VERSION ""

NS_ :

BS_:

BU_:

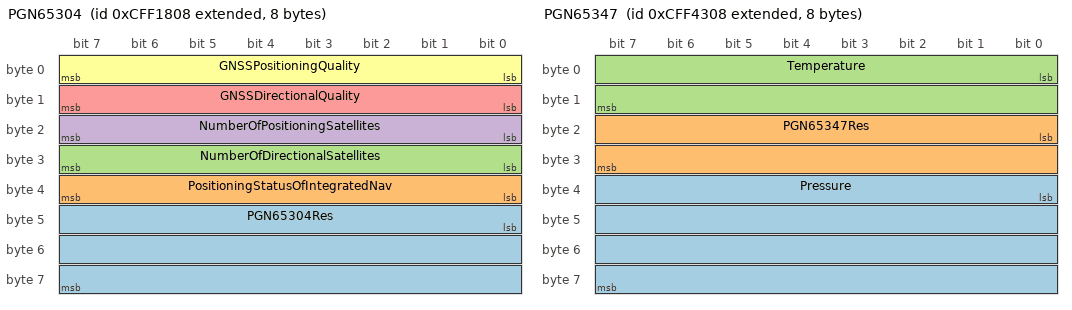
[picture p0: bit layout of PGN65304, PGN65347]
BO_ 2365528072 PGN65304: 8 Vector__XXX
 SG_ PGN65304Res : 40|24@1- (1,0) [0|0] "" Vector__XXX
 SG_ PositioningStatusOfIntegratedNav : 32|8@1- (1,0) [0|0] "" Vector__XXX
 SG_ NumberOfDirectionalSatellites : 24|8@1- (1,0) [0|0] "" Vector__XXX
 SG_ NumberOfPositioningSatellites : 16|8@1- (1,0) [0|0] "" Vector__XXX
 SG_ GNSSDirectionalQuality : 8|8@1- (1,0) [0|0] "" Vector__XXX
 SG_ GNSSPositioningQuality : 0|8@1- (1,0) [0|0] "" Vector__XXX

BO_ 2015 ODB2: 8 Vector__XXX
 SG_ Odometer : 0|64@1- (1,0) [0|0] "km/h" Vector__XXX

BO_ 2365539080 PGN65347: 8 Vector__XXX
 SG_ Pressure : 32|32@1- (0.01,0) [0|0] "Pa" Vector__XXX
SG_ PGN65347Res : 16|16@1- (1,0) [0|0] "" Vector__XXX
 SG_ Temperature : 0|16@1- (0.01,0) [0|0] "degC" Vector__XXX

BO_ 2365538568 PGN65345: 8 Vector__XXX
 SG_ PGN65345Res : 32|32@1- (1,0) [0|0] "" Vector__XXX
 SG_ Yaw : 0|32@1- (0.001,0) [0|0] "deg" Vector__XXX

BO_ 2365537544 PGN65341: 8 Vector__XXX
 SG_ Pitch : 32|32@1- (0.001,0) [0|0] "deg" Vector__XXX
 SG_ Roll : 0|32@1- (0.001,0) [0|0] "deg" Vector__XXX

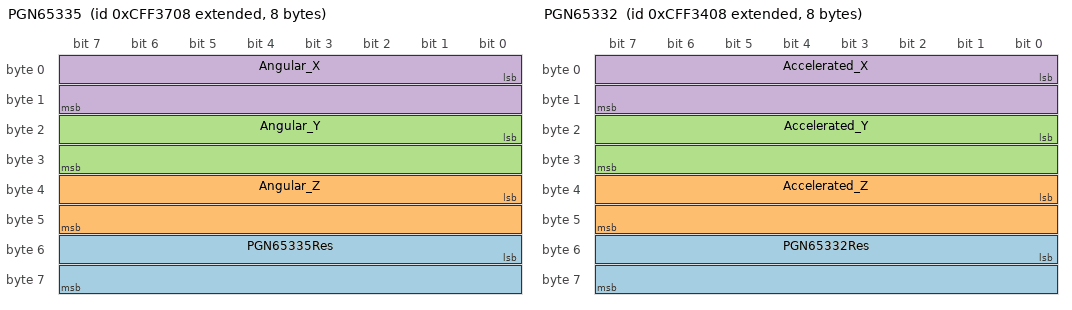
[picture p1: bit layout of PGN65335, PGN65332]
BO_ 2365536008 PGN65335: 8 Vector__XXX
 SG_ PGN65335Res : 48|16@1- (1,0) [0|0] "" Vector__XXX
 SG_ Angular_Z : 32|16@1- (0.061035,0) [0|0] "deg/s" Vector__XXX
 SG_ Angular_Y : 16|16@1- (0.061035,0) [0|0] "deg/s" Vector__XXX
 SG_ Angular_X : 0|16@1- (0.061035,0) [0|0] "deg/s" Vector__XXX

BO_ 2365535240 PGN65332: 8 Vector__XXX
 SG_ PGN65332Res : 48|16@1- (1,0) [0|0] "" Vector__XXX
 SG_ Accelerated_Z : 32|16@1- (0.00048828,0) [0|0] "G" Vector__XXX
 SG_ Accelerated_Y : 16|16@1- (0.00048828,0) [0|0] "G" Vector__XXX
 SG_ Accelerated_X : 0|16@1- (0.00048828,0) [0|0] "G" Vector__XXX

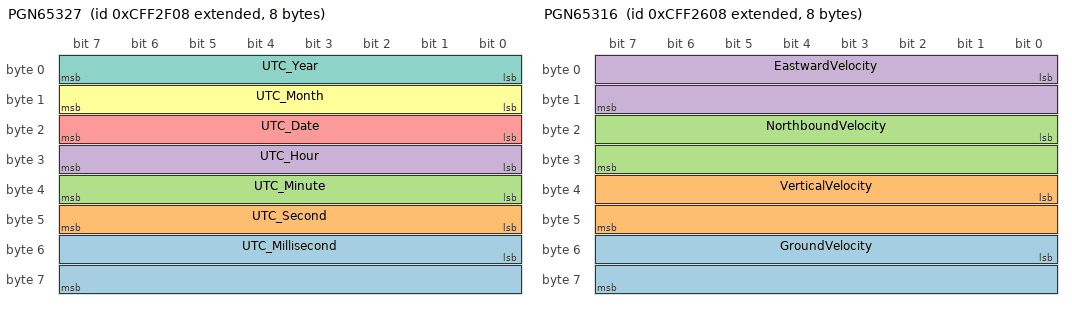
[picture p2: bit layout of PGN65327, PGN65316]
BO_ 2365533960 PGN65327: 8 Vector__XXX
 SG_ UTC_Millisecond : 48|16@1- (1,0) [0|0] "millisecond" Vector__XXX
 SG_ UTC_Second : 40|8@1- (1,0) [0|0] "second" Vector__XXX
 SG_ UTC_Minute : 32|8@1- (1,0) [0|0] "minute" Vector__XXX
 SG_ UTC_Hour : 24|8@1- (1,0) [0|0] "hour" Vector__XXX
 SG_ UTC_Date : 16|8@1- (1,0) [0|0] "date" Vector__XXX
 SG_ UTC_Month : 8|8@1- (1,0) [0|0] "month" Vector__XXX
 SG_ UTC_Year : 0|8@1- (1,0) [0|0] "year" Vector__XXX

BO_ 2365531656 PGN65316: 8 Vector__XXX
 SG_ GroundVelocity : 48|16@1- (0.01,0) [0|0] "m/s" Vector__XXX
 SG_ VerticalVelocity : 32|16@1- (0.01,0) [0|0] "m/s" Vector__XXX
 SG_ NorthboundVelocity : 16|16@1- (0.01,0) [0|0] "m/s" Vector__XXX
 SG_ EastwardVelocity : 0|16@1- (0.01,0) [0|0] "m/s" Vector__XXX

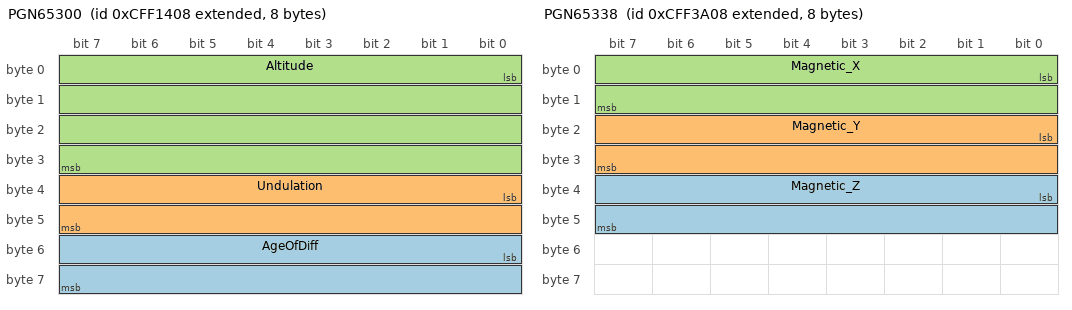
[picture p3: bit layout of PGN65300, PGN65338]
BO_ 2365527048 PGN65300: 8 Vector__XXX
 SG_ AgeOfDiff : 48|16@1- (0.01,0) [0|0] "s" Vector__XXX
 SG_ Undulation : 32|16@1- (0.01,0) [0|0] "m" Vector__XXX
 SG_ Altitude : 0|32@1- (0.01,0) [0|0] "m" Vector__XXX

BO_ 2365526024 PGN65296: 8 Vector__XXX
SG_ Longitude : 32|32@1- (1E-007,0) [0|0] "deg" Vector__XXX
SG_ Latitude : 0|32@1- (1E-007,0) [0|0] "deg" Vector__XXX

BO_ 2365536776 PGN65338: 8 Vector__XXX
 SG_ Magnetic_Z : 32|16@1- (0.030517,0) [0|0] "uT" Vector__XXX
 SG_ Magnetic_Y : 16|16@1- (0.030517,0) [0|0] "uT" Vector__XXX
 SG_ Magnetic_X : 0|16@1- (0.030517,0) [0|0] "uT" Vector__XXX

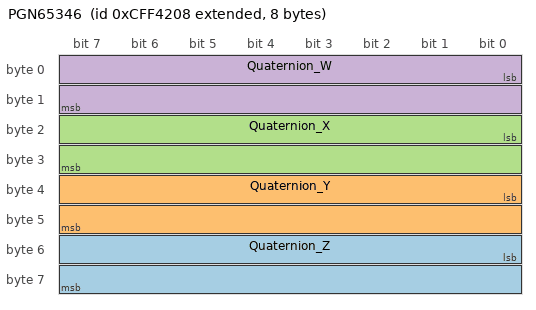
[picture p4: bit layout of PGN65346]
BO_ 2365538824 PGN65346: 8 Vector__XXX
 SG_ Quaternion_Z : 48|16@1- (0.0001,0) [0|0] "" Vector__XXX
 SG_ Quaternion_Y : 32|16@1- (0.0001,0) [0|0] "" Vector__XXX
 SG_ Quaternion_X : 16|16@1- (0.0001,0) [0|0] "" Vector__XXX
 SG_ Quaternion_W : 0|16@1- (0.0001,0) [0|0] "" Vector__XXX

BO_ 2365540872 PGN65354: 8 Vector__XXX
 SG_ Inclination_Y : 32|32@1- (0.001,0) [0|0] "deg" Vector__XXX
 SG_ Inclination_X : 0|32@1- (0.001,0) [0|0] "deg" Vector__XXX

BA_DEF_ BO_  "New_AttrDef_13" ENUM  "Cyclic","Enent";
BA_DEF_  "BusType" STRING ;
BA_DEF_DEF_  "New_AttrDef_13" "Cyclic";
BA_DEF_DEF_  "BusType" "CAN";
